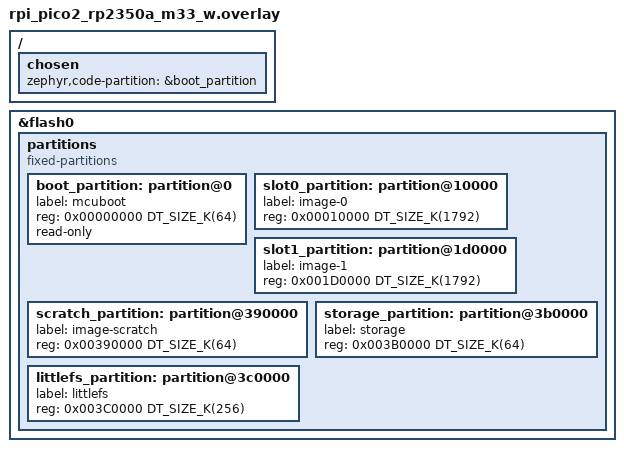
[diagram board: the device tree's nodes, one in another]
/**
 * @file      rpi_pico2_rp2350a_m33_w.overlay
 * @brief     rpi_pico2 board mcuboot overlay
 *
 * Copyright joelguittet and mender-mcu-client contributors
 *
 * Licensed under the Apache License, Version 2.0 (the "License");
 * you may not use this file except in compliance with the License.
 * You may obtain a copy of the License at
 *
 *     http://www.apache.org/licenses/LICENSE-2.0
 *
 * Unless required by applicable law or agreed to in writing, software
 * distributed under the License is distributed on an "AS IS" BASIS,
 * WITHOUT WARRANTIES OR CONDITIONS OF ANY KIND, either express or implied.
 * See the License for the specific language governing permissions and
 * limitations under the License.
 */

/ {
    chosen {
        zephyr,code-partition = &boot_partition;
    };
};

&flash0 {
    partitions {
        compatible = "fixed-partitions";
        #address-cells = <1>;
        #size-cells = <1>;
        /* Bootloader slot: 64KB */
        boot_partition: partition@0 {
            label = "mcuboot";
            reg = <0x00000000 DT_SIZE_K(64)>;
            read-only;
        };
        /* Application slot: 1792KB */
        slot0_partition: partition@10000 {
            label = "image-0";
            reg = <0x00010000 DT_SIZE_K(1792)>;
        };
        /* Update slot: 1792KB */
        slot1_partition: partition@1d0000 {
            label = "image-1";
            reg = <0x001D0000 DT_SIZE_K(1792)>;
        };
        /* Swap slot: 128KB */
        scratch_partition: partition@390000 {
            label = "image-scratch";
            reg = <0x00390000 DT_SIZE_K(64)>;
        };
        /* Storage slot: 64KB */
        storage_partition: partition@3b0000 {
            label = "storage";
            reg = <0x003B0000 DT_SIZE_K(64)>;
        };
        /* LittleFS slot: 256KB */
        littlefs_partition: partition@3c0000 {
            label = "littlefs";
            reg = <0x003C0000 DT_SIZE_K(256)>;
        };
    };
};
